AUTOSAR XML (schema 4-2-2)
package /STELLANTIS/EPT/ASWCs
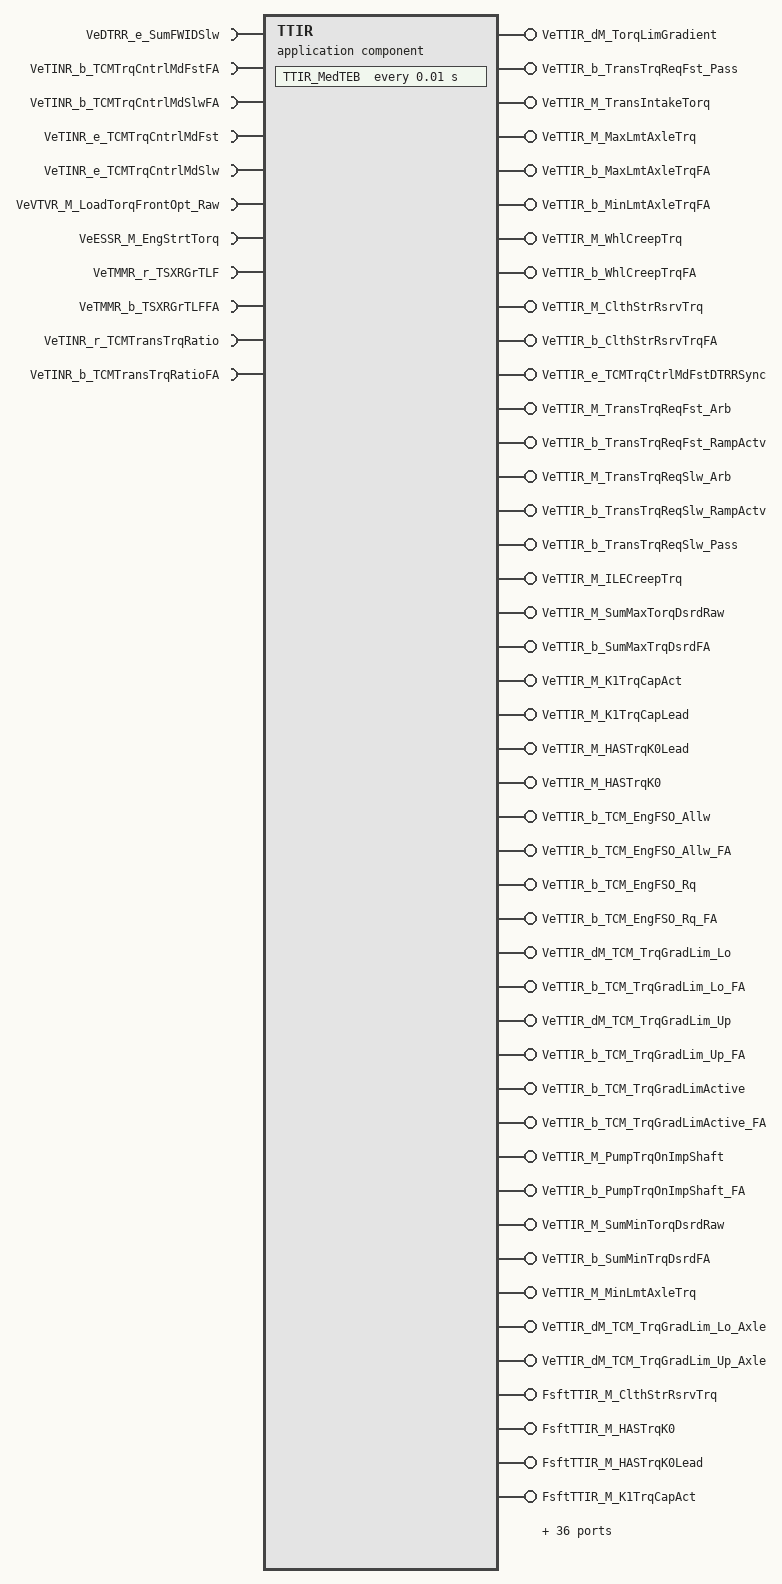
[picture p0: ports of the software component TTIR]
  application sw component type TTIR
    11 x require port:
      VeDTRR_e_SumFWIDSlw: nonqueued-receiver-com-spec{data-element=Value, init-value=CeDTRR_e_Potential}, required-interface=VeDTRR_e_SumFWIDSlw
      VeTINR_b_TCMTrqCntrlMdFstFA: nonqueued-receiver-com-spec{data-element=Value, init-value=0}, required-interface=VeTINR_b_TCMTrqCntrlMdFstFA
      VeTINR_b_TCMTrqCntrlMdSlwFA: nonqueued-receiver-com-spec{data-element=Value, init-value=0}, required-interface=VeTINR_b_TCMTrqCntrlMdSlwFA
      VeTINR_e_TCMTrqCntrlMdFst: nonqueued-receiver-com-spec{data-element=Value, init-value=CeTINR_e_None}, required-interface=VeTINR_e_TCMTrqCntrlMdFst
      VeTINR_e_TCMTrqCntrlMdSlw: nonqueued-receiver-com-spec{data-element=Value, init-value=CeTINR_e_None}, required-interface=VeTINR_e_TCMTrqCntrlMdSlw
      VeVTVR_M_LoadTorqFrontOpt_Raw: nonqueued-receiver-com-spec{data-element=Value, init-value=0}, required-interface=VeVTVR_M_LoadTorqFrontOpt_Raw
      VeESSR_M_EngStrtTorq: nonqueued-receiver-com-spec{data-element=Value, init-value=0}, required-interface=VeESSR_M_EngStrtTorq
      VeTMMR_r_TSXRGrTLF: nonqueued-receiver-com-spec{data-element=Value, init-value=0}, required-interface=VeTMMR_r_TSXRGrTLF
      VeTMMR_b_TSXRGrTLFFA: nonqueued-receiver-com-spec{data-element=Value, init-value=0}, required-interface=VeTMMR_b_TSXRGrTLFFA
      VeTINR_r_TCMTransTrqRatio: nonqueued-receiver-com-spec{data-element=Value, init-value=0}, required-interface=VeTINR_r_TCMTransTrqRatio
      VeTINR_b_TCMTransTrqRatioFA: nonqueued-receiver-com-spec{data-element=Value, init-value=0}, required-interface=VeTINR_b_TCMTransTrqRatioFA
    80 x provide port:
      VeTTIR_dM_TorqLimGradient: nonqueued-sender-com-spec{data-element=Value, init-value=0}, provided-interface=VeTTIR_dM_TorqLimGradient
      VeTTIR_b_TransTrqReqFst_Pass: nonqueued-sender-com-spec{data-element=Value, init-value=0}, provided-interface=VeTTIR_b_TransTrqReqFst_Pass
      VeTTIR_M_TransIntakeTorq: nonqueued-sender-com-spec{data-element=Value, init-value=0}, provided-interface=VeTTIR_M_TransIntakeTorq
      VeTTIR_M_MaxLmtAxleTrq: nonqueued-sender-com-spec{data-element=Value, init-value=0}, provided-interface=VeTTIR_M_MaxLmtAxleTrq
      VeTTIR_b_MaxLmtAxleTrqFA: nonqueued-sender-com-spec{data-element=Value, init-value=0}, provided-interface=VeTTIR_b_MaxLmtAxleTrqFA
      VeTTIR_b_MinLmtAxleTrqFA: nonqueued-sender-com-spec{data-element=Value, init-value=0}, provided-interface=VeTTIR_b_MinLmtAxleTrqFA
      VeTTIR_M_WhlCreepTrq: nonqueued-sender-com-spec{data-element=Value, init-value=0}, provided-interface=VeTTIR_M_WhlCreepTrq
      VeTTIR_b_WhlCreepTrqFA: nonqueued-sender-com-spec{data-element=Value, init-value=0}, provided-interface=VeTTIR_b_WhlCreepTrqFA
      VeTTIR_M_ClthStrRsrvTrq: nonqueued-sender-com-spec{data-element=Value, init-value=0}, provided-interface=VeTTIR_M_ClthStrRsrvTrq
      VeTTIR_b_ClthStrRsrvTrqFA: nonqueued-sender-com-spec{data-element=Value, init-value=0}, provided-interface=VeTTIR_b_ClthStrRsrvTrqFA
      VeTTIR_e_TCMTrqCtrlMdFstDTRRSync: nonqueued-sender-com-spec{data-element=Value, init-value=CeTINR_e_None}, provided-interface=VeTTIR_e_TCMTrqCtrlMdFstDTRRSync
      VeTTIR_M_TransTrqReqFst_Arb: nonqueued-sender-com-spec{data-element=Value, init-value=0}, provided-interface=VeTTIR_M_TransTrqReqFst_Arb
      VeTTIR_b_TransTrqReqFst_RampActv: nonqueued-sender-com-spec{data-element=Value, init-value=0}, provided-interface=VeTTIR_b_TransTrqReqFst_RampActv
      VeTTIR_M_TransTrqReqSlw_Arb: nonqueued-sender-com-spec{data-element=Value, init-value=0}, provided-interface=VeTTIR_M_TransTrqReqSlw_Arb
      VeTTIR_b_TransTrqReqSlw_RampActv: nonqueued-sender-com-spec{data-element=Value, init-value=0}, provided-interface=VeTTIR_b_TransTrqReqSlw_RampActv
      VeTTIR_b_TransTrqReqSlw_Pass: nonqueued-sender-com-spec{data-element=Value, init-value=0}, provided-interface=VeTTIR_b_TransTrqReqSlw_Pass
      VeTTIR_M_ILECreepTrq: nonqueued-sender-com-spec{data-element=Value, init-value=0}, provided-interface=VeTTIR_M_ILECreepTrq
      VeTTIR_M_SumMaxTorqDsrdRaw: nonqueued-sender-com-spec{data-element=Value, init-value=0}, provided-interface=VeTTIR_M_SumMaxTorqDsrdRaw
      VeTTIR_b_SumMaxTrqDsrdFA: nonqueued-sender-com-spec{data-element=Value, init-value=0}, provided-interface=VeTTIR_b_SumMaxTrqDsrdFA
      VeTTIR_M_K1TrqCapAct: nonqueued-sender-com-spec{data-element=Value, init-value=0}, provided-interface=VeTTIR_M_K1TrqCapAct
      VeTTIR_M_K1TrqCapLead: nonqueued-sender-com-spec{data-element=Value, init-value=0}, provided-interface=VeTTIR_M_K1TrqCapLead
      VeTTIR_M_HASTrqK0Lead: nonqueued-sender-com-spec{data-element=Value, init-value=0}, provided-interface=VeTTIR_M_HASTrqK0Lead
      VeTTIR_M_HASTrqK0: nonqueued-sender-com-spec{data-element=Value, init-value=0}, provided-interface=VeTTIR_M_HASTrqK0
      VeTTIR_b_TCM_EngFSO_Allw: nonqueued-sender-com-spec{data-element=Value, init-value=0}, provided-interface=VeTTIR_b_TCM_EngFSO_Allw
      VeTTIR_b_TCM_EngFSO_Allw_FA: nonqueued-sender-com-spec{data-element=Value, init-value=0}, provided-interface=VeTTIR_b_TCM_EngFSO_Allw_FA
      VeTTIR_b_TCM_EngFSO_Rq: nonqueued-sender-com-spec{data-element=Value, init-value=0}, provided-interface=VeTTIR_b_TCM_EngFSO_Rq
      VeTTIR_b_TCM_EngFSO_Rq_FA: nonqueued-sender-com-spec{data-element=Value, init-value=0}, provided-interface=VeTTIR_b_TCM_EngFSO_Rq_FA
      VeTTIR_dM_TCM_TrqGradLim_Lo: nonqueued-sender-com-spec{data-element=Value, init-value=0}, provided-interface=VeTTIR_dM_TCM_TrqGradLim_Lo
      VeTTIR_b_TCM_TrqGradLim_Lo_FA: nonqueued-sender-com-spec{data-element=Value, init-value=0}, provided-interface=VeTTIR_b_TCM_TrqGradLim_Lo_FA
      VeTTIR_dM_TCM_TrqGradLim_Up: nonqueued-sender-com-spec{data-element=Value, init-value=0}, provided-interface=VeTTIR_dM_TCM_TrqGradLim_Up
      VeTTIR_b_TCM_TrqGradLim_Up_FA: nonqueued-sender-com-spec{data-element=Value, init-value=0}, provided-interface=VeTTIR_b_TCM_TrqGradLim_Up_FA
      VeTTIR_b_TCM_TrqGradLimActive: nonqueued-sender-com-spec{data-element=Value, init-value=0}, provided-interface=VeTTIR_b_TCM_TrqGradLimActive
      VeTTIR_b_TCM_TrqGradLimActive_FA: nonqueued-sender-com-spec{data-element=Value, init-value=0}, provided-interface=VeTTIR_b_TCM_TrqGradLimActive_FA
      VeTTIR_M_PumpTrqOnImpShaft: nonqueued-sender-com-spec{data-element=Value, init-value=0}, provided-interface=VeTTIR_M_PumpTrqOnImpShaft
      VeTTIR_b_PumpTrqOnImpShaft_FA: nonqueued-sender-com-spec{data-element=Value, init-value=0}, provided-interface=VeTTIR_b_PumpTrqOnImpShaft_FA
      VeTTIR_M_SumMinTorqDsrdRaw: nonqueued-sender-com-spec{data-element=Value, init-value=0}, provided-interface=VeTTIR_M_SumMinTorqDsrdRaw
      VeTTIR_b_SumMinTrqDsrdFA: nonqueued-sender-com-spec{data-element=Value, init-value=0}, provided-interface=VeTTIR_b_SumMinTrqDsrdFA
      VeTTIR_M_MinLmtAxleTrq: nonqueued-sender-com-spec{data-element=Value, init-value=0}, provided-interface=VeTTIR_M_MinLmtAxleTrq
      VeTTIR_dM_TCM_TrqGradLim_Lo_Axle: nonqueued-sender-com-spec{data-element=Value, init-value=0}, provided-interface=VeTTIR_dM_TCM_TrqGradLim_Lo_Axle
      VeTTIR_dM_TCM_TrqGradLim_Up_Axle: nonqueued-sender-com-spec{data-element=Value, init-value=0}, provided-interface=VeTTIR_dM_TCM_TrqGradLim_Up_Axle
      FsftTTIR_M_ClthStrRsrvTrq: server-com-spec=FsftTTIR_M_ClthStrRsrvTrq, provided-interface=FsftTTIR_M_ClthStrRsrvTrq
      FsftTTIR_M_HASTrqK0: server-com-spec=FsftTTIR_M_HASTrqK0, provided-interface=FsftTTIR_M_HASTrqK0
      FsftTTIR_M_HASTrqK0Lead: server-com-spec=FsftTTIR_M_HASTrqK0Lead, provided-interface=FsftTTIR_M_HASTrqK0Lead
      FsftTTIR_M_K1TrqCapAct: server-com-spec=FsftTTIR_M_K1TrqCapAct, provided-interface=FsftTTIR_M_K1TrqCapAct
      FsftTTIR_M_K1TrqCapLead: server-com-spec=FsftTTIR_M_K1TrqCapLead, provided-interface=FsftTTIR_M_K1TrqCapLead
      FsftTTIR_M_MaxLmtAxleTrq: server-com-spec=FsftTTIR_M_MaxLmtAxleTrq, provided-interface=FsftTTIR_M_MaxLmtAxleTrq
      FsftTTIR_M_MinLmtAxleTrq: server-com-spec=FsftTTIR_M_MinLmtAxleTrq, provided-interface=FsftTTIR_M_MinLmtAxleTrq
      FsftTTIR_M_PumpTrqOnImpShaft: server-com-spec=FsftTTIR_M_PumpTrqOnImpShaft, provided-interface=FsftTTIR_M_PumpTrqOnImpShaft
      FsftTTIR_M_SumMaxTrqDsrd: server-com-spec=FsftTTIR_M_SumMaxTrqDsrd, provided-interface=FsftTTIR_M_SumMaxTrqDsrd
      FsftTTIR_M_SumMinTrqDsrd: server-com-spec=FsftTTIR_M_SumMinTrqDsrd, provided-interface=FsftTTIR_M_SumMinTrqDsrd
      FsftTTIR_M_TCMSumTrqReqFast: server-com-spec=FsftTTIR_M_TCMSumTrqReqFast, provided-interface=FsftTTIR_M_TCMSumTrqReqFast
      FsftTTIR_M_TCMSumTrqReqSlow: server-com-spec=FsftTTIR_M_TCMSumTrqReqSlow, provided-interface=FsftTTIR_M_TCMSumTrqReqSlow
      FsftTTIR_M_TransIntakeTorq: server-com-spec=FsftTTIR_M_TransIntakeTorq, provided-interface=FsftTTIR_M_TransIntakeTorq
      FsftTTIR_M_WhlCreepTrq: server-com-spec=FsftTTIR_M_WhlCreepTrq, provided-interface=FsftTTIR_M_WhlCreepTrq
      FsftTTIR_b_TCM_EngFSO_Allw: server-com-spec=FsftTTIR_b_TCM_EngFSO_Allw, provided-interface=FsftTTIR_b_TCM_EngFSO_Allw
      FsftTTIR_b_TCM_EngFSO_Rq: server-com-spec=FsftTTIR_b_TCM_EngFSO_Rq, provided-interface=FsftTTIR_b_TCM_EngFSO_Rq
      FsftTTIR_b_TCM_TrqGradLimActive: server-com-spec=FsftTTIR_b_TCM_TrqGradLimActive, provided-interface=FsftTTIR_b_TCM_TrqGradLimActive
      FsftTTIR_dM_TCM_TrqGradLim_Lo: server-com-spec=FsftTTIR_dM_TCM_TrqGradLim_Lo, provided-interface=FsftTTIR_dM_TCM_TrqGradLim_Lo
      FsftTTIR_dM_TCM_TrqGradLim_Up: server-com-spec=FsftTTIR_dM_TCM_TrqGradLim_Up, provided-interface=FsftTTIR_dM_TCM_TrqGradLim_Up
      PokeTTIR_M_ClthStrRsrvTrq: server-com-spec{operation=PokeTTIR_M_ClthStrRsrvTrq, queue-length=1}, provided-interface=PokeTTIR_M_ClthStrRsrvTrq
      PokeTTIR_M_HASTrqK0: server-com-spec{operation=PokeTTIR_M_HASTrqK0, queue-length=1}, provided-interface=PokeTTIR_M_HASTrqK0
      PokeTTIR_M_HASTrqK0Lead: server-com-spec{operation=PokeTTIR_M_HASTrqK0Lead, queue-length=1}, provided-interface=PokeTTIR_M_HASTrqK0Lead
      PokeTTIR_M_ILECreepTorque: server-com-spec{operation=PokeTTIR_M_ILECreepTorque, queue-length=1}, provided-interface=PokeTTIR_M_ILECreepTorque
      PokeTTIR_M_K1TrqCapAct: server-com-spec{operation=PokeTTIR_M_K1TrqCapAct, queue-length=1}, provided-interface=PokeTTIR_M_K1TrqCapAct
      PokeTTIR_M_K1TrqCapLead: server-com-spec{operation=PokeTTIR_M_K1TrqCapLead, queue-length=1}, provided-interface=PokeTTIR_M_K1TrqCapLead
      PokeTTIR_M_MaxLmtAxleTrq: server-com-spec{operation=PokeTTIR_M_MaxLmtAxleTrq, queue-length=1}, provided-interface=PokeTTIR_M_MaxLmtAxleTrq
      PokeTTIR_M_MinLmtAxleTrq: server-com-spec{operation=PokeTTIR_M_MinLmtAxleTrq, queue-length=1}, provided-interface=PokeTTIR_M_MinLmtAxleTrq
      PokeTTIR_M_PumpTrqOnImpShaft: server-com-spec{operation=PokeTTIR_M_PumpTrqOnImpShaft, queue-length=1}, provided-interface=PokeTTIR_M_PumpTrqOnImpShaft
      PokeTTIR_M_SumMaxTrqDsrd: server-com-spec{operation=PokeTTIR_M_SumMaxTrqDsrd, queue-length=1}, provided-interface=PokeTTIR_M_SumMaxTrqDsrd
      PokeTTIR_M_SumMinTrqDsrd: server-com-spec{operation=PokeTTIR_M_SumMinTrqDsrd, queue-length=1}, provided-interface=PokeTTIR_M_SumMinTrqDsrd
      PokeTTIR_M_TCMSumTrqReqFast: server-com-spec{operation=PokeTTIR_M_TCMSumTrqReqFast, queue-length=1}, provided-interface=PokeTTIR_M_TCMSumTrqReqFast
      PokeTTIR_M_TCMSumTrqReqSlow: server-com-spec{operation=PokeTTIR_M_TCMSumTrqReqSlow, queue-length=1}, provided-interface=PokeTTIR_M_TCMSumTrqReqSlow
      PokeTTIR_M_TransIntakeTorq: server-com-spec{operation=PokeTTIR_M_TransIntakeTorq, queue-length=1}, provided-interface=PokeTTIR_M_TransIntakeTorq
      PokeTTIR_M_WhlCreepTrq: server-com-spec{operation=PokeTTIR_M_WhlCreepTrq, queue-length=1}, provided-interface=PokeTTIR_M_WhlCreepTrq
      PokeTTIR_b_TCM_EngFSO_Allw: server-com-spec{operation=PokeTTIR_b_TCM_EngFSO_Allw, queue-length=1}, provided-interface=PokeTTIR_b_TCM_EngFSO_Allw
      PokeTTIR_b_TCM_EngFSO_Rq: server-com-spec{operation=PokeTTIR_b_TCM_EngFSO_Rq, queue-length=1}, provided-interface=PokeTTIR_b_TCM_EngFSO_Rq
      PokeTTIR_b_TCM_TrqGradLimActive: server-com-spec{operation=PokeTTIR_b_TCM_TrqGradLimActive, queue-length=1}, provided-interface=PokeTTIR_b_TCM_TrqGradLimActive
      PokeTTIR_dM_TCM_TrqGradLim_Lo: server-com-spec{operation=PokeTTIR_dM_TCM_TrqGradLim_Lo, queue-length=1}, provided-interface=PokeTTIR_dM_TCM_TrqGradLim_Lo
      PokeTTIR_dM_TCM_TrqGradLim_Up: server-com-spec{operation=PokeTTIR_dM_TCM_TrqGradLim_Up, queue-length=1}, provided-interface=PokeTTIR_dM_TCM_TrqGradLim_Up
      PokeTTIR_dm_TorqLimGradient: server-com-spec{operation=PokeTTIR_dm_TorqLimGradient, queue-length=1}, provided-interface=PokeTTIR_dm_TorqLimGradient
    behavior IB_TTIR: data-type-mapping=msADTtoIDTMapping, handle-termination-and-restart=NO-SUPPORT
      timing event Event_MedTEB: start-on-event=TTIR_MedTEB, period=0.01
      40 x operation invoked event:
        Event_FsftTTIR_M_ClthStrRsrvTrq: start-on-event=FsftTTIR_M_ClthStrRsrvTrq, operation=FsftTTIR_M_ClthStrRsrvTrq.FsftTTIR_M_ClthStrRsrvTrq
        Event_FsftTTIR_M_HASTrqK0: start-on-event=FsftTTIR_M_HASTrqK0, operation=FsftTTIR_M_HASTrqK0.FsftTTIR_M_HASTrqK0
        Event_FsftTTIR_M_HASTrqK0Lead: start-on-event=FsftTTIR_M_HASTrqK0Lead, operation=FsftTTIR_M_HASTrqK0Lead.FsftTTIR_M_HASTrqK0Lead
        Event_FsftTTIR_M_K1TrqCapAct: start-on-event=FsftTTIR_M_K1TrqCapAct, operation=FsftTTIR_M_K1TrqCapAct.FsftTTIR_M_K1TrqCapAct
        Event_FsftTTIR_M_K1TrqCapLead: start-on-event=FsftTTIR_M_K1TrqCapLead, operation=FsftTTIR_M_K1TrqCapLead.FsftTTIR_M_K1TrqCapLead
        Event_FsftTTIR_M_MaxLmtAxleTrq: start-on-event=FsftTTIR_M_MaxLmtAxleTrq, operation=FsftTTIR_M_MaxLmtAxleTrq.FsftTTIR_M_MaxLmtAxleTrq
        Event_FsftTTIR_M_MinLmtAxleTrq: start-on-event=FsftTTIR_M_MinLmtAxleTrq, operation=FsftTTIR_M_MinLmtAxleTrq.FsftTTIR_M_MinLmtAxleTrq
        Event_FsftTTIR_M_PumpTrqOnImpShaft: start-on-event=FsftTTIR_M_PumpTrqOnImpShaft, operation=FsftTTIR_M_PumpTrqOnImpShaft.FsftTTIR_M_PumpTrqOnImpShaft
        Event_FsftTTIR_M_SumMaxTrqDsrd: start-on-event=FsftTTIR_M_SumMaxTrqDsrd, operation=FsftTTIR_M_SumMaxTrqDsrd.FsftTTIR_M_SumMaxTrqDsrd
        Event_FsftTTIR_M_SumMinTrqDsrd: start-on-event=FsftTTIR_M_SumMinTrqDsrd, operation=FsftTTIR_M_SumMinTrqDsrd.FsftTTIR_M_SumMinTrqDsrd
        Event_FsftTTIR_M_TCMSumTrqReqFast: start-on-event=FsftTTIR_M_TCMSumTrqReqFast, operation=FsftTTIR_M_TCMSumTrqReqFast.FsftTTIR_M_TCMSumTrqReqFast
        Event_FsftTTIR_M_TCMSumTrqReqSlow: start-on-event=FsftTTIR_M_TCMSumTrqReqSlow, operation=FsftTTIR_M_TCMSumTrqReqSlow.FsftTTIR_M_TCMSumTrqReqSlow
        Event_FsftTTIR_M_TransIntakeTorq: start-on-event=FsftTTIR_M_TransIntakeTorq, operation=FsftTTIR_M_TransIntakeTorq.FsftTTIR_M_TransIntakeTorq
        Event_FsftTTIR_M_WhlCreepTrq: start-on-event=FsftTTIR_M_WhlCreepTrq, operation=FsftTTIR_M_WhlCreepTrq.FsftTTIR_M_WhlCreepTrq
        Event_FsftTTIR_b_TCM_EngFSO_Allw: start-on-event=FsftTTIR_b_TCM_EngFSO_Allw, operation=FsftTTIR_b_TCM_EngFSO_Allw.FsftTTIR_b_TCM_EngFSO_Allw
        Event_FsftTTIR_b_TCM_EngFSO_Rq: start-on-event=FsftTTIR_b_TCM_EngFSO_Rq, operation=FsftTTIR_b_TCM_EngFSO_Rq.FsftTTIR_b_TCM_EngFSO_Rq
        Event_FsftTTIR_b_TCM_TrqGradLimActive: start-on-event=FsftTTIR_b_TCM_TrqGradLimActive, operation=FsftTTIR_b_TCM_TrqGradLimActive.FsftTTIR_b_TCM_TrqGradLimActive
        Event_FsftTTIR_dM_TCM_TrqGradLim_Lo: start-on-event=FsftTTIR_dM_TCM_TrqGradLim_Lo, operation=FsftTTIR_dM_TCM_TrqGradLim_Lo.FsftTTIR_dM_TCM_TrqGradLim_Lo
        Event_FsftTTIR_dM_TCM_TrqGradLim_Up: start-on-event=FsftTTIR_dM_TCM_TrqGradLim_Up, operation=FsftTTIR_dM_TCM_TrqGradLim_Up.FsftTTIR_dM_TCM_TrqGradLim_Up
        Event_PokeTTIR_M_ClthStrRsrvTrq: start-on-event=PokeTTIR_M_ClthStrRsrvTrq, operation=PokeTTIR_M_ClthStrRsrvTrq.PokeTTIR_M_ClthStrRsrvTrq
        Event_PokeTTIR_M_HASTrqK0: start-on-event=PokeTTIR_M_HASTrqK0, operation=PokeTTIR_M_HASTrqK0.PokeTTIR_M_HASTrqK0
        Event_PokeTTIR_M_HASTrqK0Lead: start-on-event=PokeTTIR_M_HASTrqK0Lead, operation=PokeTTIR_M_HASTrqK0Lead.PokeTTIR_M_HASTrqK0Lead
        Event_PokeTTIR_M_ILECreepTorque: start-on-event=PokeTTIR_M_ILECreepTorque, operation=PokeTTIR_M_ILECreepTorque.PokeTTIR_M_ILECreepTorque
        Event_PokeTTIR_M_K1TrqCapAct: start-on-event=PokeTTIR_M_K1TrqCapAct, operation=PokeTTIR_M_K1TrqCapAct.PokeTTIR_M_K1TrqCapAct
        Event_PokeTTIR_M_K1TrqCapLead: start-on-event=PokeTTIR_M_K1TrqCapLead, operation=PokeTTIR_M_K1TrqCapLead.PokeTTIR_M_K1TrqCapLead
        Event_PokeTTIR_M_MaxLmtAxleTrq: start-on-event=PokeTTIR_M_MaxLmtAxleTrq, operation=PokeTTIR_M_MaxLmtAxleTrq.PokeTTIR_M_MaxLmtAxleTrq
        Event_PokeTTIR_M_MinLmtAxleTrq: start-on-event=PokeTTIR_M_MinLmtAxleTrq, operation=PokeTTIR_M_MinLmtAxleTrq.PokeTTIR_M_MinLmtAxleTrq
        Event_PokeTTIR_M_PumpTrqOnImpShaft: start-on-event=PokeTTIR_M_PumpTrqOnImpShaft, operation=PokeTTIR_M_PumpTrqOnImpShaft.PokeTTIR_M_PumpTrqOnImpShaft
        Event_PokeTTIR_M_SumMaxTrqDsrd: start-on-event=PokeTTIR_M_SumMaxTrqDsrd, operation=PokeTTIR_M_SumMaxTrqDsrd.PokeTTIR_M_SumMaxTrqDsrd
        Event_PokeTTIR_M_SumMinTrqDsrd: start-on-event=PokeTTIR_M_SumMinTrqDsrd, operation=PokeTTIR_M_SumMinTrqDsrd.PokeTTIR_M_SumMinTrqDsrd
        Event_PokeTTIR_M_TCMSumTrqReqFast: start-on-event=PokeTTIR_M_TCMSumTrqReqFast, operation=PokeTTIR_M_TCMSumTrqReqFast.PokeTTIR_M_TCMSumTrqReqFast
        Event_PokeTTIR_M_TCMSumTrqReqSlow: start-on-event=PokeTTIR_M_TCMSumTrqReqSlow, operation=PokeTTIR_M_TCMSumTrqReqSlow.PokeTTIR_M_TCMSumTrqReqSlow
        Event_PokeTTIR_M_TransIntakeTorq: start-on-event=PokeTTIR_M_TransIntakeTorq, operation=PokeTTIR_M_TransIntakeTorq.PokeTTIR_M_TransIntakeTorq
        Event_PokeTTIR_M_WhlCreepTrq: start-on-event=PokeTTIR_M_WhlCreepTrq, operation=PokeTTIR_M_WhlCreepTrq.PokeTTIR_M_WhlCreepTrq
        Event_PokeTTIR_b_TCM_EngFSO_Allw: start-on-event=PokeTTIR_b_TCM_EngFSO_Allw, operation=PokeTTIR_b_TCM_EngFSO_Allw.PokeTTIR_b_TCM_EngFSO_Allw
        Event_PokeTTIR_b_TCM_EngFSO_Rq: start-on-event=PokeTTIR_b_TCM_EngFSO_Rq, operation=PokeTTIR_b_TCM_EngFSO_Rq.PokeTTIR_b_TCM_EngFSO_Rq
        Event_PokeTTIR_b_TCM_TrqGradLimActive: start-on-event=PokeTTIR_b_TCM_TrqGradLimActive, operation=PokeTTIR_b_TCM_TrqGradLimActive.PokeTTIR_b_TCM_TrqGradLimActive
        Event_PokeTTIR_dM_TCM_TrqGradLim_Lo: start-on-event=PokeTTIR_dM_TCM_TrqGradLim_Lo, operation=PokeTTIR_dM_TCM_TrqGradLim_Lo.PokeTTIR_dM_TCM_TrqGradLim_Lo
        Event_PokeTTIR_dM_TCM_TrqGradLim_Up: start-on-event=PokeTTIR_dM_TCM_TrqGradLim_Up, operation=PokeTTIR_dM_TCM_TrqGradLim_Up.PokeTTIR_dM_TCM_TrqGradLim_Up
        Event_PokeTTIR_dm_TorqLimGradient: start-on-event=PokeTTIR_dm_TorqLimGradient, operation=PokeTTIR_dm_TorqLimGradient.PokeTTIR_dm_TorqLimGradient
      init event Event_TTIR_ac_Init: start-on-event=TTIR_ac_Init
      init event Event_PwrOn: start-on-event=TTIR_PwrOn
      explicit-inter-runnable-variables:
        21 x data, all with category=VALUE, sw-calibration-access=READ-ONLY, init-value=0:
          VeTTIR_b_SumMaxTrqDsrdFA_write_IRV: type=Boolean
          VeTTIR_M_TCMSumTrqReqFast_write_IRV: type=Float
          VeTTIR_b_TCMSumTrqReqFastFA_write_IRV: type=Boolean
          VeTTIR_dm_TorqLimGradient_write_IRV: type=Float
          VeTTIR_M_TransIntakeTorq_write_IRV: type=Float
          VeTTIR_M_ClthStrRsrvTrq_write_IRV: type=Float
          VeTTIR_M_K1TrqCapAct_write_IRV: type=Float
          VeTTIR_M_K1TrqCapLead_write_IRV: type=Float
          VeTTIR_M_HASTrqK0Lead_write_IRV: type=Float
          VeTTIR_M_MaxLmtAxleTrq_write_IRV: type=Float
          VeTTIR_b_MaxLmtAxleTrqFA_write_IRV: type=Boolean
          VeTTIR_M_SumMaxTrqDsrd_write_IRV: type=Float
          VeTTIR_M_SumMinTrqDsrd_write_IRV: type=Float
          VeTTIR_M_TCMSumTrqReqSlow_write_IRV: type=Float
          VeTTIR_b_TCMSumTrqReqSlowFA_write_IRV: type=Boolean
          VeTTIR_b_SumMinTrqDsrdFA_write_IRV: type=Boolean
          VeTTIR_b_MinLmtAxleTrqFA_write_IRV: type=Boolean
          VeTTIR_M_MinLmtAxleTrq_write_IRV: type=Float
          VeTTIR_dM_TCM_TrqGradLim_Lo_write_IRV: type=Float
          VeTTIR_dM_TCM_TrqGradLim_Up_write_IRV: type=Float
          VeTTIR_b_TCM_TrqGradLimActive_write_IRV: type=Boolean
      43 x runnable:
        TTIR_ac_Init
          data-send-points:
            access OUT_VeTTIR_e_TCMTrqCtrlMdFstDTRRSync_Value: accessed-variable=VeTTIR_e_TCMTrqCtrlMdFstDTRRSync.Value
        TTIR_PwrOn
          data-send-points:
            40 x access:
              OUT_VeTTIR_M_ILECreepTrq_Value: accessed-variable=VeTTIR_M_ILECreepTrq.Value
              OUT_VeTTIR_M_HASTrqK0_Value: accessed-variable=VeTTIR_M_HASTrqK0.Value
              OUT_VeTTIR_b_MaxLmtAxleTrqFA_Value: accessed-variable=VeTTIR_b_MaxLmtAxleTrqFA.Value
              OUT_VeTTIR_b_MinLmtAxleTrqFA_Value: accessed-variable=VeTTIR_b_MinLmtAxleTrqFA.Value
              OUT_VeTTIR_b_WhlCreepTrqFA_Value: accessed-variable=VeTTIR_b_WhlCreepTrqFA.Value
              OUT_VeTTIR_M_WhlCreepTrq_Value: accessed-variable=VeTTIR_M_WhlCreepTrq.Value
              OUT_VeTTIR_b_ClthStrRsrvTrqFA_Value: accessed-variable=VeTTIR_b_ClthStrRsrvTrqFA.Value
              OUT_VeTTIR_e_TCMTrqCtrlMdFstDTRRSync_Value: accessed-variable=VeTTIR_e_TCMTrqCtrlMdFstDTRRSync.Value
              OUT_VeTTIR_M_TransIntakeTorq_Value: accessed-variable=VeTTIR_M_TransIntakeTorq.Value
              OUT_VeTTIR_M_TransTrqReqFst_Arb_Value: accessed-variable=VeTTIR_M_TransTrqReqFst_Arb.Value
              OUT_VeTTIR_b_TransTrqReqFst_RampActv_Value: accessed-variable=VeTTIR_b_TransTrqReqFst_RampActv.Value
              OUT_VeTTIR_M_TransTrqReqSlw_Arb_Value: accessed-variable=VeTTIR_M_TransTrqReqSlw_Arb.Value
              OUT_VeTTIR_b_TransTrqReqSlw_RampActv_Value: accessed-variable=VeTTIR_b_TransTrqReqSlw_RampActv.Value
              OUT_VeTTIR_b_TransTrqReqSlw_Pass_Value: accessed-variable=VeTTIR_b_TransTrqReqSlw_Pass.Value
              OUT_VeTTIR_dM_TorqLimGradient_Value: accessed-variable=VeTTIR_dM_TorqLimGradient.Value
              OUT_VeTTIR_b_TransTrqReqFst_Pass_Value: accessed-variable=VeTTIR_b_TransTrqReqFst_Pass.Value
              OUT_VeTTIR_M_MaxLmtAxleTrq_Value: accessed-variable=VeTTIR_M_MaxLmtAxleTrq.Value
              OUT_VeTTIR_M_MinLmtAxleTrq_Value: accessed-variable=VeTTIR_M_MinLmtAxleTrq.Value
              OUT_VeTTIR_M_ClthStrRsrvTrq_Value: accessed-variable=VeTTIR_M_ClthStrRsrvTrq.Value
              OUT_VeTTIR_M_SumMaxTorqDsrdRaw_Value: accessed-variable=VeTTIR_M_SumMaxTorqDsrdRaw.Value
              OUT_VeTTIR_b_SumMaxTrqDsrdFA_Value: accessed-variable=VeTTIR_b_SumMaxTrqDsrdFA.Value
              OUT_VeTTIR_M_K1TrqCapAct_Value: accessed-variable=VeTTIR_M_K1TrqCapAct.Value
              OUT_VeTTIR_M_K1TrqCapLead_Value: accessed-variable=VeTTIR_M_K1TrqCapLead.Value
              OUT_VeTTIR_M_HASTrqK0Lead_Value: accessed-variable=VeTTIR_M_HASTrqK0Lead.Value
              OUT_VeTTIR_b_TCM_EngFSO_Allw_Value: accessed-variable=VeTTIR_b_TCM_EngFSO_Allw.Value
              OUT_VeTTIR_b_TCM_EngFSO_Allw_FA_Value: accessed-variable=VeTTIR_b_TCM_EngFSO_Allw_FA.Value
              OUT_VeTTIR_b_TCM_EngFSO_Rq_Value: accessed-variable=VeTTIR_b_TCM_EngFSO_Rq.Value
              OUT_VeTTIR_b_TCM_EngFSO_Rq_FA_Value: accessed-variable=VeTTIR_b_TCM_EngFSO_Rq_FA.Value
              OUT_VeTTIR_b_TCM_TrqGradLim_Lo_FA_Value: accessed-variable=VeTTIR_b_TCM_TrqGradLim_Lo_FA.Value
              OUT_VeTTIR_b_TCM_TrqGradLim_Up_FA_Value: accessed-variable=VeTTIR_b_TCM_TrqGradLim_Up_FA.Value
              OUT_VeTTIR_b_TCM_TrqGradLimActive_Value: accessed-variable=VeTTIR_b_TCM_TrqGradLimActive.Value
              OUT_VeTTIR_b_TCM_TrqGradLimActive_FA_Value: accessed-variable=VeTTIR_b_TCM_TrqGradLimActive_FA.Value
              OUT_VeTTIR_M_PumpTrqOnImpShaft_Value: accessed-variable=VeTTIR_M_PumpTrqOnImpShaft.Value
              OUT_VeTTIR_b_PumpTrqOnImpShaft_FA_Value: accessed-variable=VeTTIR_b_PumpTrqOnImpShaft_FA.Value
              OUT_VeTTIR_M_SumMinTorqDsrdRaw_Value: accessed-variable=VeTTIR_M_SumMinTorqDsrdRaw.Value
              OUT_VeTTIR_b_SumMinTrqDsrdFA_Value: accessed-variable=VeTTIR_b_SumMinTrqDsrdFA.Value
              OUT_VeTTIR_dM_TCM_TrqGradLim_Lo_Value: accessed-variable=VeTTIR_dM_TCM_TrqGradLim_Lo.Value
              OUT_VeTTIR_dM_TCM_TrqGradLim_Up_Value: accessed-variable=VeTTIR_dM_TCM_TrqGradLim_Up.Value
              OUT_VeTTIR_dM_TCM_TrqGradLim_Lo_Axle_Value: accessed-variable=VeTTIR_dM_TCM_TrqGradLim_Lo_Axle.Value
              OUT_VeTTIR_dM_TCM_TrqGradLim_Up_Axle_Value: accessed-variable=VeTTIR_dM_TCM_TrqGradLim_Up_Axle.Value
          written-local-variables:
            21 x access:
              WV_VeTTIR_M_ClthStrRsrvTrq_write_IRV: accessed-variable=VeTTIR_M_ClthStrRsrvTrq_write_IRV
              WV_VeTTIR_b_TCM_TrqGradLimActive_write_IRV: accessed-variable=VeTTIR_b_TCM_TrqGradLimActive_write_IRV
              WV_VeTTIR_dM_TCM_TrqGradLim_Lo_write_IRV: accessed-variable=VeTTIR_dM_TCM_TrqGradLim_Lo_write_IRV
              WV_VeTTIR_dM_TCM_TrqGradLim_Up_write_IRV: accessed-variable=VeTTIR_dM_TCM_TrqGradLim_Up_write_IRV
              WV_VeTTIR_M_HASTrqK0Lead_write_IRV: accessed-variable=VeTTIR_M_HASTrqK0Lead_write_IRV
              WV_VeTTIR_M_K1TrqCapAct_write_IRV: accessed-variable=VeTTIR_M_K1TrqCapAct_write_IRV
              WV_VeTTIR_M_K1TrqCapLead_write_IRV: accessed-variable=VeTTIR_M_K1TrqCapLead_write_IRV
              WV_VeTTIR_M_MaxLmtAxleTrq_write_IRV: accessed-variable=VeTTIR_M_MaxLmtAxleTrq_write_IRV
              WV_VeTTIR_M_MinLmtAxleTrq_write_IRV: accessed-variable=VeTTIR_M_MinLmtAxleTrq_write_IRV
              WV_VeTTIR_M_SumMaxTrqDsrd_write_IRV: accessed-variable=VeTTIR_M_SumMaxTrqDsrd_write_IRV
              WV_VeTTIR_M_SumMinTrqDsrd_write_IRV: accessed-variable=VeTTIR_M_SumMinTrqDsrd_write_IRV
              WV_VeTTIR_M_TCMSumTrqReqFast_write_IRV: accessed-variable=VeTTIR_M_TCMSumTrqReqFast_write_IRV
              WV_VeTTIR_M_TCMSumTrqReqSlow_write_IRV: accessed-variable=VeTTIR_M_TCMSumTrqReqSlow_write_IRV
              WV_VeTTIR_M_TransIntakeTorq_write_IRV: accessed-variable=VeTTIR_M_TransIntakeTorq_write_IRV
              WV_VeTTIR_b_MaxLmtAxleTrqFA_write_IRV: accessed-variable=VeTTIR_b_MaxLmtAxleTrqFA_write_IRV
              WV_VeTTIR_b_MinLmtAxleTrqFA_write_IRV: accessed-variable=VeTTIR_b_MinLmtAxleTrqFA_write_IRV
              WV_VeTTIR_b_SumMaxTrqDsrdFA_write_IRV: accessed-variable=VeTTIR_b_SumMaxTrqDsrdFA_write_IRV
              WV_VeTTIR_b_SumMinTrqDsrdFA_write_IRV: accessed-variable=VeTTIR_b_SumMinTrqDsrdFA_write_IRV
              WV_VeTTIR_b_TCMSumTrqReqFastFA_write_IRV: accessed-variable=VeTTIR_b_TCMSumTrqReqFastFA_write_IRV
              WV_VeTTIR_b_TCMSumTrqReqSlowFA_write_IRV: accessed-variable=VeTTIR_b_TCMSumTrqReqSlowFA_write_IRV
              WV_VeTTIR_dm_TorqLimGradient_write_IRV: accessed-variable=VeTTIR_dm_TorqLimGradient_write_IRV
        TTIR_MedTEB
          data-receive-point-by-arguments:
            11 x access:
              IN_VeDTRR_e_SumFWIDSlw_Value: accessed-variable=VeDTRR_e_SumFWIDSlw.Value
              IN_VeESSR_M_EngStrtTorq_Value: accessed-variable=VeESSR_M_EngStrtTorq.Value
              IN_VeTINR_b_TCMTransTrqRatioFA_Value: accessed-variable=VeTINR_b_TCMTransTrqRatioFA.Value
              IN_VeTINR_b_TCMTrqCntrlMdFstFA_Value: accessed-variable=VeTINR_b_TCMTrqCntrlMdFstFA.Value
              IN_VeTINR_b_TCMTrqCntrlMdSlwFA_Value: accessed-variable=VeTINR_b_TCMTrqCntrlMdSlwFA.Value
              IN_VeTINR_e_TCMTrqCntrlMdFst_Value: accessed-variable=VeTINR_e_TCMTrqCntrlMdFst.Value
              IN_VeTINR_e_TCMTrqCntrlMdSlw_Value: accessed-variable=VeTINR_e_TCMTrqCntrlMdSlw.Value
              IN_VeTINR_r_TCMTransTrqRatio_Value: accessed-variable=VeTINR_r_TCMTransTrqRatio.Value
              IN_VeTMMR_b_TSXRGrTLFFA_Value: accessed-variable=VeTMMR_b_TSXRGrTLFFA.Value
              IN_VeTMMR_r_TSXRGrTLF_Value: accessed-variable=VeTMMR_r_TSXRGrTLF.Value
              IN_VeVTVR_M_LoadTorqFrontOpt_Raw_Value: accessed-variable=VeVTVR_M_LoadTorqFrontOpt_Raw.Value
          data-send-points:
            23 x access:
              OUT_VeTTIR_e_TCMTrqCtrlMdFstDTRRSync_Value: accessed-variable=VeTTIR_e_TCMTrqCtrlMdFstDTRRSync.Value
              OUT_VeTTIR_M_TransTrqReqFst_Arb_Value: accessed-variable=VeTTIR_M_TransTrqReqFst_Arb.Value
              OUT_VeTTIR_b_TransTrqReqFst_RampActv_Value: accessed-variable=VeTTIR_b_TransTrqReqFst_RampActv.Value
              OUT_VeTTIR_b_TransTrqReqFst_Pass_Value: accessed-variable=VeTTIR_b_TransTrqReqFst_Pass.Value
              OUT_VeTTIR_M_TransIntakeTorq_Value: accessed-variable=VeTTIR_M_TransIntakeTorq.Value
              OUT_VeTTIR_dM_TorqLimGradient_Value: accessed-variable=VeTTIR_dM_TorqLimGradient.Value
              OUT_VeTTIR_M_MaxLmtAxleTrq_Value: accessed-variable=VeTTIR_M_MaxLmtAxleTrq.Value
              OUT_VeTTIR_M_ClthStrRsrvTrq_Value: accessed-variable=VeTTIR_M_ClthStrRsrvTrq.Value
              OUT_VeTTIR_M_SumMaxTorqDsrdRaw_Value: accessed-variable=VeTTIR_M_SumMaxTorqDsrdRaw.Value
              OUT_VeTTIR_b_SumMaxTrqDsrdFA_Value: accessed-variable=VeTTIR_b_SumMaxTrqDsrdFA.Value
              OUT_VeTTIR_M_K1TrqCapAct_Value: accessed-variable=VeTTIR_M_K1TrqCapAct.Value
              OUT_VeTTIR_M_K1TrqCapLead_Value: accessed-variable=VeTTIR_M_K1TrqCapLead.Value
              OUT_VeTTIR_M_HASTrqK0Lead_Value: accessed-variable=VeTTIR_M_HASTrqK0Lead.Value
              OUT_VeTTIR_M_TransTrqReqSlw_Arb_Value: accessed-variable=VeTTIR_M_TransTrqReqSlw_Arb.Value
              OUT_VeTTIR_b_TransTrqReqSlw_RampActv_Value: accessed-variable=VeTTIR_b_TransTrqReqSlw_RampActv.Value
              OUT_VeTTIR_b_TransTrqReqSlw_Pass_Value: accessed-variable=VeTTIR_b_TransTrqReqSlw_Pass.Value
              OUT_VeTTIR_M_SumMinTorqDsrdRaw_Value: accessed-variable=VeTTIR_M_SumMinTorqDsrdRaw.Value
              OUT_VeTTIR_b_SumMinTrqDsrdFA_Value: accessed-variable=VeTTIR_b_SumMinTrqDsrdFA.Value
              OUT_VeTTIR_M_MinLmtAxleTrq_Value: accessed-variable=VeTTIR_M_MinLmtAxleTrq.Value
              OUT_VeTTIR_dM_TCM_TrqGradLim_Lo_Value: accessed-variable=VeTTIR_dM_TCM_TrqGradLim_Lo.Value
              OUT_VeTTIR_dM_TCM_TrqGradLim_Up_Value: accessed-variable=VeTTIR_dM_TCM_TrqGradLim_Up.Value
              OUT_VeTTIR_dM_TCM_TrqGradLim_Lo_Axle_Value: accessed-variable=VeTTIR_dM_TCM_TrqGradLim_Lo_Axle.Value
              OUT_VeTTIR_dM_TCM_TrqGradLim_Up_Axle_Value: accessed-variable=VeTTIR_dM_TCM_TrqGradLim_Up_Axle.Value
          read-local-variables:
            21 x access:
              RV_VeTTIR_M_ClthStrRsrvTrq_write_IRV: accessed-variable=VeTTIR_M_ClthStrRsrvTrq_write_IRV
              RV_VeTTIR_M_HASTrqK0Lead_write_IRV: accessed-variable=VeTTIR_M_HASTrqK0Lead_write_IRV
              RV_VeTTIR_M_K1TrqCapAct_write_IRV: accessed-variable=VeTTIR_M_K1TrqCapAct_write_IRV
              RV_VeTTIR_M_K1TrqCapLead_write_IRV: accessed-variable=VeTTIR_M_K1TrqCapLead_write_IRV
              RV_VeTTIR_M_MaxLmtAxleTrq_write_IRV: accessed-variable=VeTTIR_M_MaxLmtAxleTrq_write_IRV
              RV_VeTTIR_M_MinLmtAxleTrq_write_IRV: accessed-variable=VeTTIR_M_MinLmtAxleTrq_write_IRV
              RV_VeTTIR_M_SumMaxTrqDsrd_write_IRV: accessed-variable=VeTTIR_M_SumMaxTrqDsrd_write_IRV
              RV_VeTTIR_M_SumMinTrqDsrd_write_IRV: accessed-variable=VeTTIR_M_SumMinTrqDsrd_write_IRV
              RV_VeTTIR_M_TCMSumTrqReqFast_write_IRV: accessed-variable=VeTTIR_M_TCMSumTrqReqFast_write_IRV
              RV_VeTTIR_M_TCMSumTrqReqSlow_write_IRV: accessed-variable=VeTTIR_M_TCMSumTrqReqSlow_write_IRV
              RV_VeTTIR_M_TransIntakeTorq_write_IRV: accessed-variable=VeTTIR_M_TransIntakeTorq_write_IRV
              RV_VeTTIR_b_MaxLmtAxleTrqFA_write_IRV: accessed-variable=VeTTIR_b_MaxLmtAxleTrqFA_write_IRV
              RV_VeTTIR_b_MinLmtAxleTrqFA_write_IRV: accessed-variable=VeTTIR_b_MinLmtAxleTrqFA_write_IRV
              RV_VeTTIR_b_SumMaxTrqDsrdFA_write_IRV: accessed-variable=VeTTIR_b_SumMaxTrqDsrdFA_write_IRV
              RV_VeTTIR_b_SumMinTrqDsrdFA_write_IRV: accessed-variable=VeTTIR_b_SumMinTrqDsrdFA_write_IRV
              RV_VeTTIR_b_TCMSumTrqReqFastFA_write_IRV: accessed-variable=VeTTIR_b_TCMSumTrqReqFastFA_write_IRV
              RV_VeTTIR_b_TCMSumTrqReqSlowFA_write_IRV: accessed-variable=VeTTIR_b_TCMSumTrqReqSlowFA_write_IRV
              RV_VeTTIR_b_TCM_TrqGradLimActive_write_IRV: accessed-variable=VeTTIR_b_TCM_TrqGradLimActive_write_IRV
              RV_VeTTIR_dM_TCM_TrqGradLim_Lo_write_IRV: accessed-variable=VeTTIR_dM_TCM_TrqGradLim_Lo_write_IRV
              RV_VeTTIR_dM_TCM_TrqGradLim_Up_write_IRV: accessed-variable=VeTTIR_dM_TCM_TrqGradLim_Up_write_IRV
              RV_VeTTIR_dm_TorqLimGradient_write_IRV: accessed-variable=VeTTIR_dm_TorqLimGradient_write_IRV
        FsftTTIR_M_ClthStrRsrvTrq
          data-send-points:
            access OUT_VeTTIR_b_ClthStrRsrvTrqFA_Value: accessed-variable=VeTTIR_b_ClthStrRsrvTrqFA.Value
          written-local-variables:
            access WV_VeTTIR_M_ClthStrRsrvTrq_write_IRV: accessed-variable=VeTTIR_M_ClthStrRsrvTrq_write_IRV
        FsftTTIR_M_HASTrqK0
          data-send-points:
            access OUT_VeTTIR_M_HASTrqK0_Value: accessed-variable=VeTTIR_M_HASTrqK0.Value
        FsftTTIR_M_HASTrqK0Lead
          written-local-variables:
            access WV_VeTTIR_M_HASTrqK0Lead_write_IRV: accessed-variable=VeTTIR_M_HASTrqK0Lead_write_IRV
        FsftTTIR_M_K1TrqCapAct
          written-local-variables:
            access WV_VeTTIR_M_K1TrqCapAct_write_IRV: accessed-variable=VeTTIR_M_K1TrqCapAct_write_IRV
        FsftTTIR_M_K1TrqCapLead
          written-local-variables:
            access WV_VeTTIR_M_K1TrqCapLead_write_IRV: accessed-variable=VeTTIR_M_K1TrqCapLead_write_IRV
        FsftTTIR_M_MaxLmtAxleTrq
          data-send-points:
            access OUT_VeTTIR_b_MaxLmtAxleTrqFA_Value: accessed-variable=VeTTIR_b_MaxLmtAxleTrqFA.Value
          written-local-variables:
            access WV_VeTTIR_M_MaxLmtAxleTrq_write_IRV: accessed-variable=VeTTIR_M_MaxLmtAxleTrq_write_IRV
            access WV_VeTTIR_b_MaxLmtAxleTrqFA_write_IRV: accessed-variable=VeTTIR_b_MaxLmtAxleTrqFA_write_IRV
        FsftTTIR_M_MinLmtAxleTrq
          data-send-points:
            access OUT_VeTTIR_b_MinLmtAxleTrqFA_Value: accessed-variable=VeTTIR_b_MinLmtAxleTrqFA.Value
          written-local-variables:
            access WV_VeTTIR_M_MinLmtAxleTrq_write_IRV: accessed-variable=VeTTIR_M_MinLmtAxleTrq_write_IRV
            access WV_VeTTIR_b_MinLmtAxleTrqFA_write_IRV: accessed-variable=VeTTIR_b_MinLmtAxleTrqFA_write_IRV
        FsftTTIR_M_PumpTrqOnImpShaft
          data-send-points:
            access OUT_VeTTIR_M_PumpTrqOnImpShaft_Value: accessed-variable=VeTTIR_M_PumpTrqOnImpShaft.Value
            access OUT_VeTTIR_b_PumpTrqOnImpShaft_FA_Value: accessed-variable=VeTTIR_b_PumpTrqOnImpShaft_FA.Value
        FsftTTIR_M_SumMaxTrqDsrd
          written-local-variables:
            access WV_VeTTIR_M_SumMaxTrqDsrd_write_IRV: accessed-variable=VeTTIR_M_SumMaxTrqDsrd_write_IRV
            access WV_VeTTIR_b_SumMaxTrqDsrdFA_write_IRV: accessed-variable=VeTTIR_b_SumMaxTrqDsrdFA_write_IRV
        FsftTTIR_M_SumMinTrqDsrd
          written-local-variables:
            access WV_VeTTIR_M_SumMinTrqDsrd_write_IRV: accessed-variable=VeTTIR_M_SumMinTrqDsrd_write_IRV
            access WV_VeTTIR_b_SumMinTrqDsrdFA_write_IRV: accessed-variable=VeTTIR_b_SumMinTrqDsrdFA_write_IRV
        FsftTTIR_M_TCMSumTrqReqFast
          written-local-variables:
            access WV_VeTTIR_M_TCMSumTrqReqFast_write_IRV: accessed-variable=VeTTIR_M_TCMSumTrqReqFast_write_IRV
            access WV_VeTTIR_b_TCMSumTrqReqFastFA_write_IRV: accessed-variable=VeTTIR_b_TCMSumTrqReqFastFA_write_IRV
        FsftTTIR_M_TCMSumTrqReqSlow
          written-local-variables:
            access WV_VeTTIR_M_TCMSumTrqReqSlow_write_IRV: accessed-variable=VeTTIR_M_TCMSumTrqReqSlow_write_IRV
            access WV_VeTTIR_b_TCMSumTrqReqSlowFA_write_IRV: accessed-variable=VeTTIR_b_TCMSumTrqReqSlowFA_write_IRV
        FsftTTIR_M_TransIntakeTorq
          written-local-variables:
            access WV_VeTTIR_M_TransIntakeTorq_write_IRV: accessed-variable=VeTTIR_M_TransIntakeTorq_write_IRV
        FsftTTIR_M_WhlCreepTrq
          data-send-points:
            access OUT_VeTTIR_M_WhlCreepTrq_Value: accessed-variable=VeTTIR_M_WhlCreepTrq.Value
            access OUT_VeTTIR_b_WhlCreepTrqFA_Value: accessed-variable=VeTTIR_b_WhlCreepTrqFA.Value
        FsftTTIR_b_TCM_EngFSO_Allw
          data-send-points:
            access OUT_VeTTIR_b_TCM_EngFSO_Allw_FA_Value: accessed-variable=VeTTIR_b_TCM_EngFSO_Allw_FA.Value
        FsftTTIR_b_TCM_EngFSO_Rq
          data-send-points:
            access OUT_VeTTIR_b_TCM_EngFSO_Rq_FA_Value: accessed-variable=VeTTIR_b_TCM_EngFSO_Rq_FA.Value
        FsftTTIR_b_TCM_TrqGradLimActive
          data-send-points:
            access OUT_VeTTIR_b_TCM_TrqGradLimActive_FA_Value: accessed-variable=VeTTIR_b_TCM_TrqGradLimActive_FA.Value
        FsftTTIR_dM_TCM_TrqGradLim_Lo
          data-send-points:
            access OUT_VeTTIR_b_TCM_TrqGradLim_Lo_FA_Value: accessed-variable=VeTTIR_b_TCM_TrqGradLim_Lo_FA.Value
          written-local-variables:
            access WV_VeTTIR_dM_TCM_TrqGradLim_Lo_write_IRV: accessed-variable=VeTTIR_dM_TCM_TrqGradLim_Lo_write_IRV
        FsftTTIR_dM_TCM_TrqGradLim_Up
          data-send-points:
            access OUT_VeTTIR_b_TCM_TrqGradLim_Up_FA_Value: accessed-variable=VeTTIR_b_TCM_TrqGradLim_Up_FA.Value
          written-local-variables:
            access WV_VeTTIR_dM_TCM_TrqGradLim_Up_write_IRV: accessed-variable=VeTTIR_dM_TCM_TrqGradLim_Up_write_IRV
        PokeTTIR_M_ClthStrRsrvTrq
          data-send-points:
            access OUT_VeTTIR_b_ClthStrRsrvTrqFA_Value: accessed-variable=VeTTIR_b_ClthStrRsrvTrqFA.Value
          written-local-variables:
            access WV_VeTTIR_M_ClthStrRsrvTrq_write_IRV: accessed-variable=VeTTIR_M_ClthStrRsrvTrq_write_IRV
        PokeTTIR_M_HASTrqK0
          data-send-points:
            access OUT_VeTTIR_M_HASTrqK0_Value: accessed-variable=VeTTIR_M_HASTrqK0.Value
        PokeTTIR_M_HASTrqK0Lead
          written-local-variables:
            access WV_VeTTIR_M_HASTrqK0Lead_write_IRV: accessed-variable=VeTTIR_M_HASTrqK0Lead_write_IRV
        PokeTTIR_M_ILECreepTorque
          data-send-points:
            access OUT_VeTTIR_M_ILECreepTrq_Value: accessed-variable=VeTTIR_M_ILECreepTrq.Value
        PokeTTIR_M_K1TrqCapAct
          written-local-variables:
            access WV_VeTTIR_M_K1TrqCapAct_write_IRV: accessed-variable=VeTTIR_M_K1TrqCapAct_write_IRV
        PokeTTIR_M_K1TrqCapLead
          written-local-variables:
            access WV_VeTTIR_M_K1TrqCapLead_write_IRV: accessed-variable=VeTTIR_M_K1TrqCapLead_write_IRV
        PokeTTIR_M_MaxLmtAxleTrq
          data-send-points:
            access OUT_VeTTIR_b_MaxLmtAxleTrqFA_Value: accessed-variable=VeTTIR_b_MaxLmtAxleTrqFA.Value
          written-local-variables:
            access WV_VeTTIR_M_MaxLmtAxleTrq_write_IRV: accessed-variable=VeTTIR_M_MaxLmtAxleTrq_write_IRV
            access WV_VeTTIR_b_MaxLmtAxleTrqFA_write_IRV: accessed-variable=VeTTIR_b_MaxLmtAxleTrqFA_write_IRV
        PokeTTIR_M_MinLmtAxleTrq
          data-send-points:
            access OUT_VeTTIR_b_MinLmtAxleTrqFA_Value: accessed-variable=VeTTIR_b_MinLmtAxleTrqFA.Value
          written-local-variables:
            access WV_VeTTIR_M_MinLmtAxleTrq_write_IRV: accessed-variable=VeTTIR_M_MinLmtAxleTrq_write_IRV
            access WV_VeTTIR_b_MinLmtAxleTrqFA_write_IRV: accessed-variable=VeTTIR_b_MinLmtAxleTrqFA_write_IRV
        PokeTTIR_M_PumpTrqOnImpShaft
          data-send-points:
            access OUT_VeTTIR_M_PumpTrqOnImpShaft_Value: accessed-variable=VeTTIR_M_PumpTrqOnImpShaft.Value
            access OUT_VeTTIR_b_PumpTrqOnImpShaft_FA_Value: accessed-variable=VeTTIR_b_PumpTrqOnImpShaft_FA.Value
        PokeTTIR_M_SumMaxTrqDsrd
          written-local-variables:
            access WV_VeTTIR_M_SumMaxTrqDsrd_write_IRV: accessed-variable=VeTTIR_M_SumMaxTrqDsrd_write_IRV
            access WV_VeTTIR_b_SumMaxTrqDsrdFA_write_IRV: accessed-variable=VeTTIR_b_SumMaxTrqDsrdFA_write_IRV
        PokeTTIR_M_SumMinTrqDsrd
          written-local-variables:
            access WV_VeTTIR_M_SumMinTrqDsrd_write_IRV: accessed-variable=VeTTIR_M_SumMinTrqDsrd_write_IRV
            access WV_VeTTIR_b_SumMinTrqDsrdFA_write_IRV: accessed-variable=VeTTIR_b_SumMinTrqDsrdFA_write_IRV
        PokeTTIR_M_TCMSumTrqReqFast
          written-local-variables:
            access WV_VeTTIR_M_TCMSumTrqReqFast_write_IRV: accessed-variable=VeTTIR_M_TCMSumTrqReqFast_write_IRV
            access WV_VeTTIR_b_TCMSumTrqReqFastFA_write_IRV: accessed-variable=VeTTIR_b_TCMSumTrqReqFastFA_write_IRV
        PokeTTIR_M_TCMSumTrqReqSlow
          written-local-variables:
            access WV_VeTTIR_M_TCMSumTrqReqSlow_write_IRV: accessed-variable=VeTTIR_M_TCMSumTrqReqSlow_write_IRV
            access WV_VeTTIR_b_TCMSumTrqReqSlowFA_write_IRV: accessed-variable=VeTTIR_b_TCMSumTrqReqSlowFA_write_IRV
        PokeTTIR_M_TransIntakeTorq
          written-local-variables:
            access WV_VeTTIR_M_TransIntakeTorq_write_IRV: accessed-variable=VeTTIR_M_TransIntakeTorq_write_IRV
        PokeTTIR_M_WhlCreepTrq
          data-send-points:
            access OUT_VeTTIR_M_WhlCreepTrq_Value: accessed-variable=VeTTIR_M_WhlCreepTrq.Value
            access OUT_VeTTIR_b_WhlCreepTrqFA_Value: accessed-variable=VeTTIR_b_WhlCreepTrqFA.Value
        PokeTTIR_b_TCM_EngFSO_Allw
          data-send-points:
            access OUT_VeTTIR_b_TCM_EngFSO_Allw_Value: accessed-variable=VeTTIR_b_TCM_EngFSO_Allw.Value
            access OUT_VeTTIR_b_TCM_EngFSO_Allw_FA_Value: accessed-variable=VeTTIR_b_TCM_EngFSO_Allw_FA.Value
        PokeTTIR_b_TCM_EngFSO_Rq
          data-send-points:
            access OUT_VeTTIR_b_TCM_EngFSO_Rq_Value: accessed-variable=VeTTIR_b_TCM_EngFSO_Rq.Value
            access OUT_VeTTIR_b_TCM_EngFSO_Rq_FA_Value: accessed-variable=VeTTIR_b_TCM_EngFSO_Rq_FA.Value
        PokeTTIR_b_TCM_TrqGradLimActive
          data-send-points:
            access OUT_VeTTIR_b_TCM_TrqGradLimActive_Value: accessed-variable=VeTTIR_b_TCM_TrqGradLimActive.Value
            access OUT_VeTTIR_b_TCM_TrqGradLimActive_FA_Value: accessed-variable=VeTTIR_b_TCM_TrqGradLimActive_FA.Value
          written-local-variables:
            access WV_VeTTIR_b_TCM_TrqGradLimActive_write_IRV: accessed-variable=VeTTIR_b_TCM_TrqGradLimActive_write_IRV
        PokeTTIR_dM_TCM_TrqGradLim_Lo
          data-send-points:
            access OUT_VeTTIR_b_TCM_TrqGradLim_Lo_FA_Value: accessed-variable=VeTTIR_b_TCM_TrqGradLim_Lo_FA.Value
          written-local-variables:
            access WV_VeTTIR_dM_TCM_TrqGradLim_Lo_write_IRV: accessed-variable=VeTTIR_dM_TCM_TrqGradLim_Lo_write_IRV
        PokeTTIR_dM_TCM_TrqGradLim_Up
          data-send-points:
            access OUT_VeTTIR_b_TCM_TrqGradLim_Up_FA_Value: accessed-variable=VeTTIR_b_TCM_TrqGradLim_Up_FA.Value
          written-local-variables:
            access WV_VeTTIR_dM_TCM_TrqGradLim_Up_write_IRV: accessed-variable=VeTTIR_dM_TCM_TrqGradLim_Up_write_IRV
        PokeTTIR_dm_TorqLimGradient
          written-local-variables:
            access WV_VeTTIR_dm_TorqLimGradient_write_IRV: accessed-variable=VeTTIR_dm_TorqLimGradient_write_IRV
